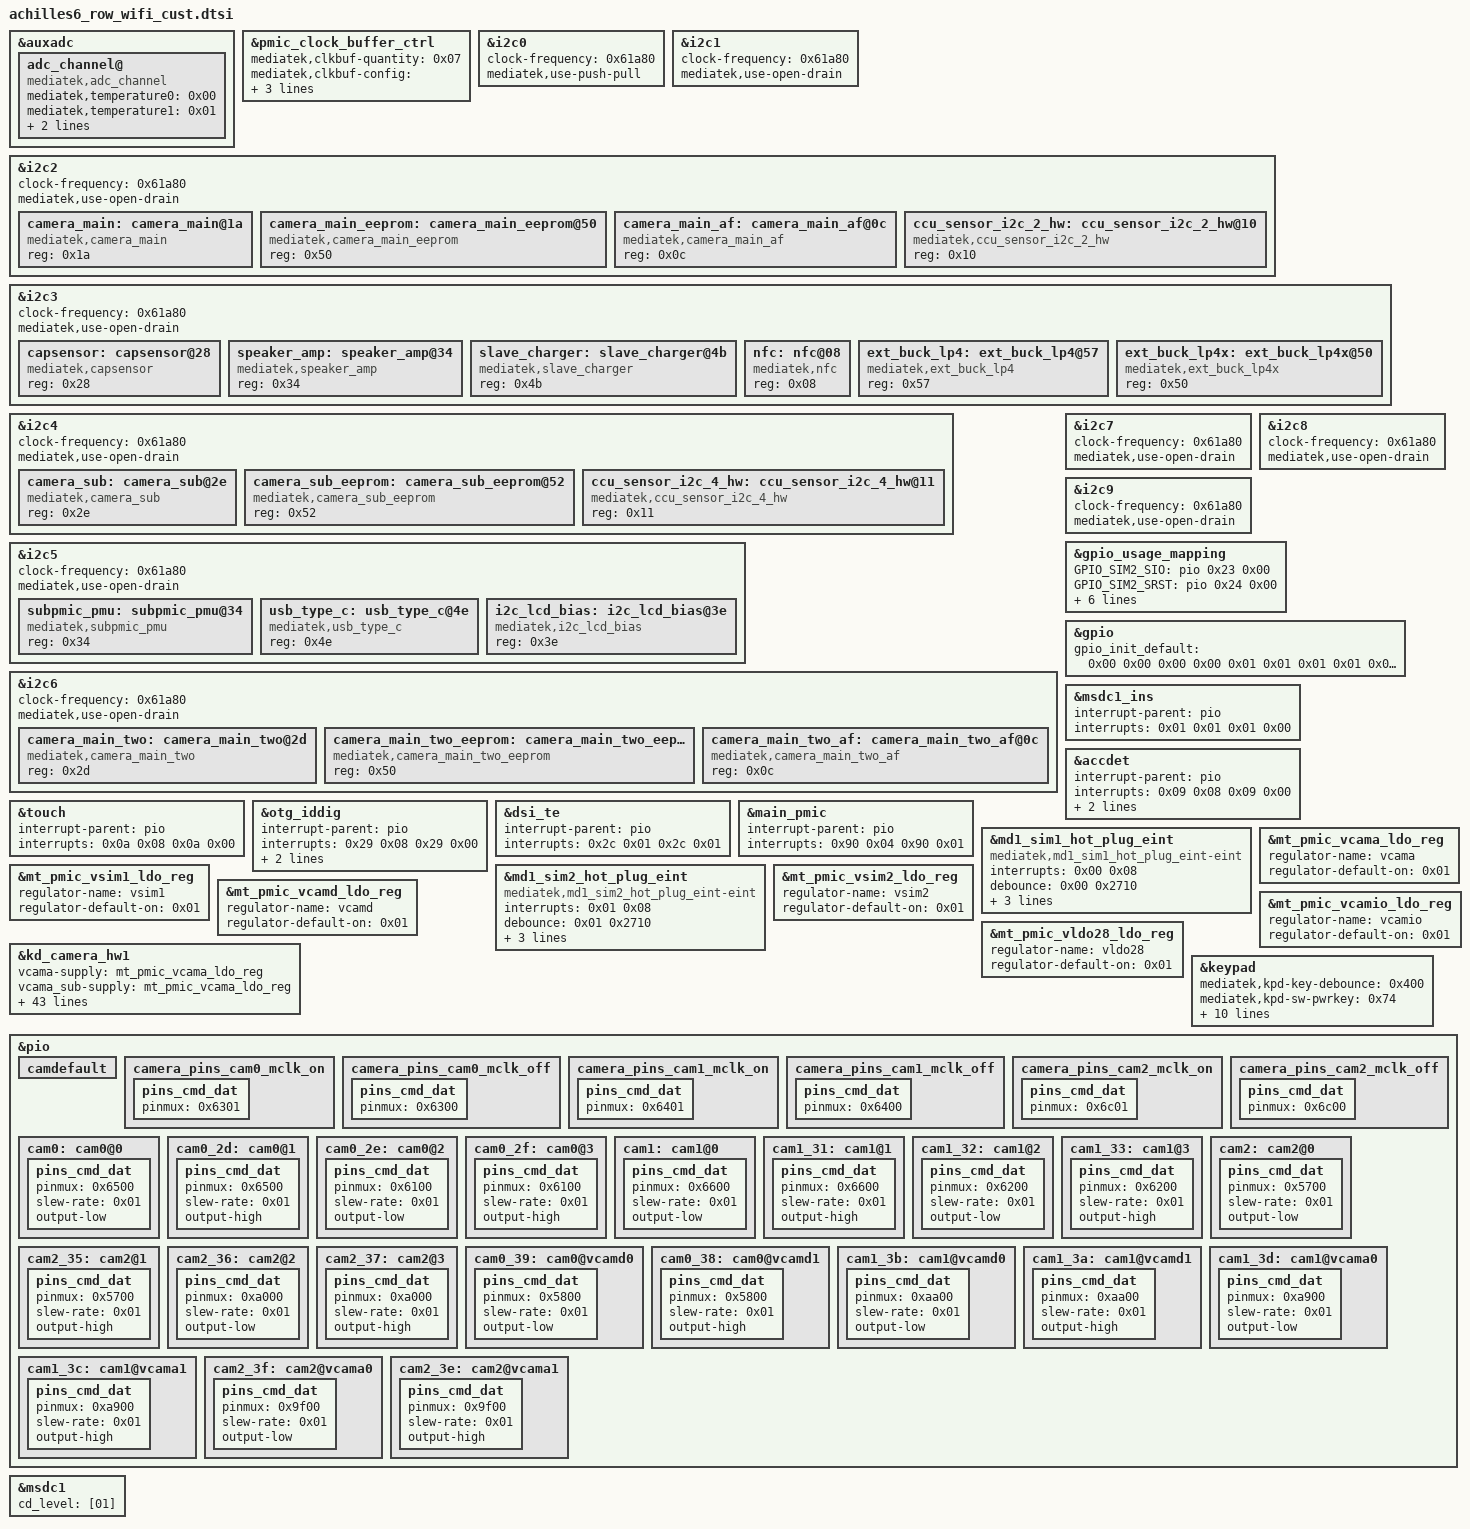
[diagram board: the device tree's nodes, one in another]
// SPDX-License-Identifier: GPL-2.0
/*
 * TB-X606F DrvGen output (GPIO, EINT, I2C, PMIC, KPD, camera pins), taken
 * from the stock Android 10 S301068 overlay. The 4.9 source drop's .dws is
 * older than the shipped hardware description, so it is not used.
 */

&auxadc {

	adc_channel@ {
		compatible = "mediatek,adc_channel";
		mediatek,temperature0 = <0x00>;
		mediatek,temperature1 = <0x01>;
		mediatek,adc_fdd_rf_params_dynamic_custom_ch = <0x02>;
		status = "okay";
	};
};

&pmic_clock_buffer_ctrl {
	mediatek,clkbuf-quantity = <0x07>;
	mediatek,clkbuf-config = <0x02 0x01 0x01 0x02 0x00 0x00 0x00>;
	mediatek,clkbuf-driving-current = <0x01 0x01 0x01 0x01 0x01 0x01 0x01>;
	status = "okay";
};

&i2c0 {
	#address-cells = <0x01>;
	#size-cells = <0x00>;
	clock-frequency = <0x61a80>;
	mediatek,use-push-pull;
};

&i2c1 {
	#address-cells = <0x01>;
	#size-cells = <0x00>;
	clock-frequency = <0x61a80>;
	mediatek,use-open-drain;
};

&i2c2 {
	#address-cells = <0x01>;
	#size-cells = <0x00>;
	clock-frequency = <0x61a80>;
	mediatek,use-open-drain;

	camera_main: camera_main@1a {
		compatible = "mediatek,camera_main";
		reg = <0x1a>;
		status = "okay";
	};

	camera_main_eeprom: camera_main_eeprom@50 {
		compatible = "mediatek,camera_main_eeprom";
		reg = <0x50>;
		status = "okay";
	};

	camera_main_af: camera_main_af@0c {
		compatible = "mediatek,camera_main_af";
		reg = <0x0c>;
		status = "okay";
	};

	ccu_sensor_i2c_2_hw: ccu_sensor_i2c_2_hw@10 {
		compatible = "mediatek,ccu_sensor_i2c_2_hw";
		reg = <0x10>;
		status = "okay";
	};
};

&i2c3 {
	#address-cells = <0x01>;
	#size-cells = <0x00>;
	clock-frequency = <0x61a80>;
	mediatek,use-open-drain;

	capsensor: capsensor@28 {
		compatible = "mediatek,capsensor";
		reg = <0x28>;
		status = "okay";
	};

	speaker_amp: speaker_amp@34 {
		compatible = "mediatek,speaker_amp";
		reg = <0x34>;
		status = "okay";
	};

	slave_charger: slave_charger@4b {
		compatible = "mediatek,slave_charger";
		reg = <0x4b>;
		status = "okay";
	};

	nfc: nfc@08 {
		compatible = "mediatek,nfc";
		reg = <0x08>;
		status = "okay";
	};

	ext_buck_lp4: ext_buck_lp4@57 {
		compatible = "mediatek,ext_buck_lp4";
		reg = <0x57>;
		status = "okay";
	};

	ext_buck_lp4x: ext_buck_lp4x@50 {
		compatible = "mediatek,ext_buck_lp4x";
		reg = <0x50>;
		status = "okay";
	};
};

&i2c4 {
	#address-cells = <0x01>;
	#size-cells = <0x00>;
	clock-frequency = <0x61a80>;
	mediatek,use-open-drain;

	camera_sub: camera_sub@2e {
		compatible = "mediatek,camera_sub";
		reg = <0x2e>;
		status = "okay";
	};

	camera_sub_eeprom: camera_sub_eeprom@52 {
		compatible = "mediatek,camera_sub_eeprom";
		reg = <0x52>;
		status = "okay";
	};

	ccu_sensor_i2c_4_hw: ccu_sensor_i2c_4_hw@11 {
		compatible = "mediatek,ccu_sensor_i2c_4_hw";
		reg = <0x11>;
		status = "okay";
	};
};

&i2c5 {
	#address-cells = <0x01>;
	#size-cells = <0x00>;
	clock-frequency = <0x61a80>;
	mediatek,use-open-drain;

	subpmic_pmu: subpmic_pmu@34 {
		compatible = "mediatek,subpmic_pmu";
		reg = <0x34>;
		status = "okay";
	};

	usb_type_c: usb_type_c@4e {
		compatible = "mediatek,usb_type_c";
		reg = <0x4e>;
		status = "okay";
	};

	i2c_lcd_bias: i2c_lcd_bias@3e {
		compatible = "mediatek,i2c_lcd_bias";
		reg = <0x3e>;
		status = "okay";
	};
};

&i2c6 {
	#address-cells = <0x01>;
	#size-cells = <0x00>;
	clock-frequency = <0x61a80>;
	mediatek,use-open-drain;

	camera_main_two: camera_main_two@2d {
		compatible = "mediatek,camera_main_two";
		reg = <0x2d>;
		status = "okay";
	};

	camera_main_two_eeprom: camera_main_two_eeprom@50 {
		compatible = "mediatek,camera_main_two_eeprom";
		reg = <0x50>;
		status = "okay";
	};

	camera_main_two_af: camera_main_two_af@0c {
		compatible = "mediatek,camera_main_two_af";
		reg = <0x0c>;
		status = "okay";
	};
};

&i2c7 {
	#address-cells = <0x01>;
	#size-cells = <0x00>;
	clock-frequency = <0x61a80>;
	mediatek,use-open-drain;
};

&i2c8 {
	#address-cells = <0x01>;
	#size-cells = <0x00>;
	clock-frequency = <0x61a80>;
	mediatek,use-open-drain;
};

&i2c9 {
	#address-cells = <0x01>;
	#size-cells = <0x00>;
	clock-frequency = <0x61a80>;
	mediatek,use-open-drain;
};

&gpio_usage_mapping {
	GPIO_SIM2_SIO = <&pio 0x23 0x00>;
	GPIO_SIM2_SRST = <&pio 0x24 0x00>;
	GPIO_SIM2_SCLK = <&pio 0x25 0x00>;
	GPIO_SIM1_SCLK = <&pio 0x26 0x00>;
	GPIO_SIM1_SRST = <&pio 0x27 0x00>;
	GPIO_SIM1_SIO = <&pio 0x28 0x00>;
	GPIO_SIM2_HOT_PLUG = <&pio 0x2e 0x00>;
	GPIO_SIM1_HOT_PLUG = <&pio 0x2f 0x00>;
};

&gpio {
	gpio_init_default = <
		0x00 0x00 0x00 0x00 0x01 0x01 0x01
		0x01 0x00 0x00 0x00 0x01 0x00 0x01
		0x02 0x00 0x00 0x00 0x00 0x00 0x01
		0x03 0x00 0x00 0x00 0x01 0x01 0x00
		0x04 0x00 0x00 0x00 0x01 0x01 0x00
		0x05 0x05 0x01 0x00 0x00 0x00 0x00
		0x06 0x00 0x01 0x00 0x01 0x01 0x00
		0x07 0x00 0x00 0x00 0x01 0x01 0x00
		0x08 0x07 0x00 0x00 0x01 0x01 0x00
		0x09 0x00 0x00 0x00 0x01 0x01 0x00
		0x0a 0x00 0x00 0x00 0x01 0x01 0x00
		0x0b 0x00 0x00 0x00 0x01 0x01 0x00
		0x0c 0x00 0x00 0x00 0x01 0x01 0x00
		0x0d 0x03 0x00 0x00 0x01 0x00 0x00
		0x0e 0x03 0x01 0x00 0x00 0x00 0x00
		0x0f 0x03 0x01 0x00 0x00 0x00 0x00
		0x10 0x03 0x01 0x00 0x00 0x00 0x00
		0x11 0x06 0x00 0x00 0x01 0x00 0x00
		0x12 0x06 0x01 0x00 0x00 0x00 0x00
		0x13 0x06 0x01 0x00 0x00 0x00 0x00
		0x14 0x06 0x01 0x00 0x00 0x00 0x00
		0x15 0x01 0x00 0x00 0x01 0x01 0x00
		0x16 0x01 0x01 0x00 0x01 0x00 0x00
		0x17 0x01 0x01 0x00 0x01 0x01 0x00
		0x18 0x01 0x01 0x00 0x01 0x00 0x00
		0x19 0x03 0x00 0x00 0x01 0x01 0x00
		0x1a 0x03 0x00 0x00 0x01 0x01 0x00
		0x1b 0x03 0x01 0x00 0x00 0x00 0x00
		0x1c 0x00 0x01 0x00 0x00 0x00 0x00
		0x1d 0x01 0x01 0x00 0x00 0x00 0x01
		0x1e 0x01 0x00 0x00 0x01 0x01 0x01
		0x1f 0x01 0x00 0x00 0x01 0x01 0x01
		0x20 0x01 0x00 0x00 0x01 0x01 0x01
		0x21 0x01 0x00 0x00 0x01 0x01 0x01
		0x22 0x01 0x00 0x00 0x01 0x01 0x01
		0x23 0x01 0x00 0x00 0x01 0x01 0x00
		0x24 0x01 0x01 0x00 0x00 0x00 0x00
		0x25 0x01 0x01 0x00 0x00 0x00 0x00
		0x26 0x01 0x01 0x00 0x00 0x00 0x00
		0x27 0x01 0x01 0x00 0x00 0x00 0x00
		0x28 0x01 0x00 0x00 0x01 0x01 0x00
		0x29 0x00 0x00 0x00 0x01 0x01 0x00
		0x2a 0x00 0x01 0x00 0x01 0x00 0x00
		0x2b 0x00 0x00 0x00 0x01 0x00 0x00
		0x2c 0x01 0x00 0x00 0x01 0x00 0x00
		0x2d 0x00 0x01 0x00 0x00 0x00 0x00
		0x2e 0x01 0x00 0x00 0x01 0x01 0x00
		0x2f 0x01 0x00 0x00 0x01 0x01 0x00
		0x30 0x01 0x00 0x00 0x01 0x01 0x01
		0x31 0x01 0x00 0x00 0x01 0x01 0x01
		0x32 0x01 0x00 0x00 0x01 0x01 0x01
		0x33 0x01 0x00 0x00 0x01 0x01 0x01
		0x34 0x01 0x01 0x00 0x01 0x00 0x00
		0x35 0x01 0x01 0x00 0x01 0x00 0x00
		0x36 0x01 0x01 0x00 0x01 0x00 0x00
		0x37 0x01 0x01 0x00 0x01 0x00 0x00
		0x38 0x01 0x01 0x00 0x01 0x00 0x00
		0x39 0x01 0x01 0x00 0x01 0x00 0x00
		0x3a 0x00 0x00 0x00 0x01 0x00 0x00
		0x3b 0x01 0x00 0x00 0x01 0x00 0x00
		0x3c 0x01 0x00 0x00 0x01 0x00 0x00
		0x3d 0x01 0x00 0x00 0x01 0x00 0x00
		0x3e 0x01 0x00 0x00 0x01 0x00 0x00
		0x3f 0x01 0x00 0x00 0x01 0x00 0x00
		0x40 0x01 0x00 0x00 0x01 0x00 0x00
		0x41 0x01 0x00 0x00 0x01 0x00 0x00
		0x42 0x01 0x00 0x00 0x01 0x00 0x00
		0x43 0x01 0x00 0x00 0x01 0x00 0x00
		0x44 0x01 0x00 0x00 0x01 0x00 0x00
		0x45 0x01 0x01 0x00 0x01 0x00 0x00
		0x46 0x01 0x01 0x00 0x01 0x00 0x00
		0x47 0x01 0x01 0x00 0x01 0x00 0x00
		0x48 0x01 0x01 0x00 0x01 0x00 0x00
		0x49 0x01 0x01 0x00 0x01 0x00 0x00
		0x4a 0x01 0x01 0x00 0x01 0x00 0x00
		0x4b 0x01 0x01 0x00 0x01 0x00 0x00
		0x4c 0x01 0x01 0x00 0x01 0x00 0x00
		0x4d 0x01 0x01 0x00 0x01 0x00 0x00
		0x4e 0x01 0x01 0x00 0x01 0x00 0x00
		0x4f 0x01 0x00 0x00 0x01 0x00 0x00
		0x50 0x01 0x00 0x00 0x01 0x00 0x00
		0x51 0x01 0x00 0x00 0x01 0x01 0x01
		0x52 0x01 0x00 0x00 0x01 0x01 0x01
		0x53 0x01 0x00 0x00 0x01 0x01 0x01
		0x54 0x01 0x00 0x00 0x01 0x01 0x01
		0x55 0x01 0x01 0x00 0x01 0x00 0x00
		0x56 0x01 0x01 0x00 0x01 0x00 0x00
		0x57 0x00 0x01 0x01 0x00 0x00 0x00
		0x58 0x00 0x01 0x00 0x01 0x00 0x00
		0x59 0x01 0x00 0x00 0x01 0x00 0x00
		0x5a 0x02 0x01 0x00 0x00 0x00 0x00
		0x5b 0x00 0x01 0x00 0x01 0x00 0x00
		0x5c 0x01 0x01 0x00 0x00 0x00 0x00
		0x5d 0x01 0x00 0x00 0x01 0x01 0x00
		0x5e 0x01 0x00 0x00 0x01 0x01 0x00
		0x5f 0x01 0x00 0x00 0x01 0x01 0x00
		0x60 0x01 0x01 0x00 0x00 0x00 0x00
		0x61 0x00 0x01 0x00 0x00 0x00 0x00
		0x62 0x00 0x01 0x00 0x00 0x00 0x00
		0x63 0x01 0x01 0x00 0x00 0x00 0x00
		0x64 0x01 0x01 0x00 0x00 0x00 0x00
		0x65 0x00 0x01 0x01 0x00 0x00 0x00
		0x66 0x00 0x01 0x01 0x00 0x00 0x00
		0x67 0x01 0x00 0x00 0x01 0x01 0x01
		0x68 0x01 0x00 0x00 0x01 0x01 0x01
		0x69 0x01 0x00 0x00 0x01 0x01 0x01
		0x6a 0x01 0x00 0x00 0x01 0x01 0x01
		0x6b 0x02 0x01 0x00 0x00 0x00 0x00
		0x6c 0x01 0x01 0x00 0x00 0x00 0x00
		0x6d 0x02 0x00 0x00 0x01 0x01 0x00
		0x6e 0x00 0x00 0x00 0x01 0x00 0x00
		0x6f 0x00 0x00 0x00 0x01 0x00 0x00
		0x70 0x00 0x00 0x00 0x01 0x00 0x00
		0x71 0x00 0x00 0x00 0x01 0x00 0x00
		0x72 0x00 0x00 0x00 0x01 0x00 0x00
		0x73 0x00 0x00 0x00 0x01 0x00 0x00
		0x74 0x00 0x00 0x00 0x01 0x00 0x00
		0x75 0x00 0x00 0x00 0x01 0x00 0x00
		0x76 0x00 0x00 0x00 0x01 0x00 0x00
		0x77 0x00 0x00 0x00 0x01 0x00 0x00
		0x78 0x00 0x00 0x00 0x01 0x00 0x00
		0x79 0x00 0x00 0x00 0x01 0x00 0x00
		0x7a 0x01 0x00 0x00 0x01 0x01 0x01
		0x7b 0x01 0x00 0x00 0x01 0x01 0x01
		0x7c 0x01 0x01 0x00 0x00 0x00 0x01
		0x7d 0x01 0x00 0x00 0x01 0x01 0x01
		0x7e 0x01 0x00 0x00 0x01 0x01 0x01
		0x7f 0x01 0x00 0x00 0x01 0x01 0x01
		0x80 0x01 0x00 0x00 0x01 0x01 0x01
		0x81 0x01 0x00 0x00 0x01 0x01 0x01
		0x82 0x01 0x00 0x00 0x01 0x01 0x01
		0x83 0x01 0x00 0x00 0x01 0x00 0x01
		0x84 0x01 0x00 0x00 0x01 0x01 0x01
		0x85 0x01 0x01 0x01 0x00 0x00 0x01
		0x86 0x01 0x00 0x00 0x01 0x00 0x01
		0x87 0x01 0x01 0x00 0x00 0x00 0x00
		0x88 0x01 0x01 0x00 0x00 0x00 0x00
		0x89 0x01 0x01 0x00 0x00 0x00 0x00
		0x8a 0x01 0x01 0x00 0x00 0x00 0x00
		0x8b 0x01 0x01 0x00 0x00 0x00 0x00
		0x8c 0x01 0x00 0x00 0x01 0x00 0x00
		0x8d 0x01 0x00 0x00 0x01 0x00 0x00
		0x8e 0x01 0x00 0x00 0x01 0x00 0x00
		0x8f 0x01 0x00 0x00 0x01 0x00 0x00
		0x90 0x01 0x00 0x00 0x01 0x00 0x00
		0x91 0x01 0x01 0x01 0x00 0x00 0x00
		0x92 0x01 0x00 0x00 0x01 0x00 0x00
		0x93 0x01 0x01 0x00 0x00 0x00 0x00
		0x94 0x01 0x01 0x00 0x00 0x00 0x00
		0x95 0x01 0x01 0x00 0x00 0x00 0x00
		0x96 0x06 0x00 0x00 0x01 0x01 0x00
		0x97 0x00 0x01 0x00 0x00 0x00 0x00
		0x98 0x00 0x00 0x00 0x00 0x00 0x00
		0x99 0x00 0x01 0x00 0x00 0x00 0x00
		0x9a 0x00 0x01 0x00 0x00 0x00 0x00
		0x9b 0x07 0x01 0x00 0x00 0x00 0x00
		0x9c 0x07 0x00 0x00 0x01 0x00 0x00
		0x9d 0x07 0x00 0x00 0x01 0x00 0x00
		0x9e 0x07 0x00 0x00 0x01 0x00 0x00
		0x9f 0x00 0x01 0x01 0x00 0x00 0x00
		0xa0 0x00 0x01 0x00 0x00 0x00 0x00
		0xa1 0x01 0x00 0x00 0x01 0x01 0x01
		0xa2 0x01 0x00 0x00 0x01 0x01 0x01
		0xa3 0x00 0x00 0x00 0x00 0x00 0x00
		0xa4 0x00 0x00 0x00 0x00 0x00 0x00
		0xa5 0x00 0x00 0x00 0x01 0x00 0x00
		0xa6 0x00 0x00 0x00 0x01 0x00 0x00
		0xa7 0x00 0x01 0x00 0x01 0x01 0x00
		0xa8 0x00 0x01 0x00 0x01 0x01 0x00
		0xa9 0x00 0x01 0x00 0x00 0x00 0x00
		0xaa 0x00 0x00 0x00 0x00 0x00 0x00
		0xab 0x00 0x00 0x00 0x01 0x00 0x00
		0xac 0x00 0x01 0x00 0x00 0x00 0x00
		0xad 0x00 0x01 0x00 0x00 0x00 0x00
		0xae 0x00 0x01 0x00 0x00 0x00 0x00
		0xaf 0x00 0x01 0x00 0x00 0x00 0x00
		0xb0 0x00 0x01 0x00 0x00 0x00 0x00
		0xb1 0x00 0x01 0x00 0x00 0x00 0x00
		0xb2 0x00 0x01 0x01 0x01 0x01 0x00
		0xb3 0x00 0x00 0x00 0x01 0x00 0x00
	>;
};

&msdc1_ins {
	interrupt-parent = <&pio>;
	interrupts = <0x01 0x01 0x01 0x00>;
	status = "okay";
};

&accdet {
	interrupt-parent = <&pio>;
	interrupts = <0x09 0x08 0x09 0x00>;
	deb-gpios = <&pio 0x09 0x00>;
	debounce = <0x3e800>;
	status = "okay";
};

&touch {
	interrupt-parent = <&pio>;
	interrupts = <0x0a 0x08 0x0a 0x00>;
	status = "okay";
};

&otg_iddig {
	interrupt-parent = <&pio>;
	interrupts = <0x29 0x02 0x29 0x00>;
	status = "okay";
};

&dsi_te {
	interrupt-parent = <&pio>;
	interrupts = <0x2c 0x01 0x2c 0x01>;
	status = "okay";
};

&main_pmic {
	interrupt-parent = <&pio>;
	interrupts = <0x90 0x04 0x90 0x01>;
	status = "okay";
};

&md1_sim1_hot_plug_eint {
	compatible = "mediatek,md1_sim1_hot_plug_eint-eint";
	interrupts = <0x00 0x08>;
	debounce = <0x00 0x2710>;
	dedicated = <0x00 0x00>;
	src_pin = <0x00 0x01>;
	sockettype = <0x00 0x00>;
	status = "okay";
};

&md1_sim2_hot_plug_eint {
	compatible = "mediatek,md1_sim2_hot_plug_eint-eint";
	interrupts = <0x01 0x08>;
	debounce = <0x01 0x2710>;
	dedicated = <0x01 0x00>;
	src_pin = <0x01 0x02>;
	sockettype = <0x01 0x00>;
	status = "okay";
};

&mt_pmic_vcama_ldo_reg {
	regulator-name = "vcama";
	regulator-default-on = <0x01>;
	status = "okay";
};

&mt_pmic_vsim1_ldo_reg {
	regulator-name = "vsim1";
	regulator-default-on = <0x01>;
	status = "okay";
};

&mt_pmic_vsim2_ldo_reg {
	regulator-name = "vsim2";
	regulator-default-on = <0x01>;
	status = "okay";
};

&mt_pmic_vcamd_ldo_reg {
	regulator-name = "vcamd";
	regulator-default-on = <0x01>;
	status = "okay";
};

&mt_pmic_vcamio_ldo_reg {
	regulator-name = "vcamio";
	regulator-default-on = <0x01>;
	status = "okay";
};

&mt_pmic_vldo28_ldo_reg {
	regulator-name = "vldo28";
	regulator-default-on = <0x01>;
	status = "okay";
};

&kd_camera_hw1 {
	vcama-supply = <&mt_pmic_vcama_ldo_reg>;
	vcama_sub-supply = <&mt_pmic_vcama_ldo_reg>;
	vcamd_main2-supply = <&mt_pmic_vcamd_ldo_reg>;
	vcamd_sub-supply = <&mt_pmic_vcamd_ldo_reg>;
	vcamio-supply = <&mt_pmic_vcamio_ldo_reg>;
	vcamio_sub-supply = <&mt_pmic_vcamio_ldo_reg>;
	vcamio_main2-supply = <&mt_pmic_vcamio_ldo_reg>;
	vcamaf-supply = <&mt_pmic_vldo28_ldo_reg>;
	status = "okay";
};

&touch {
	status = "okay";
};

&keypad {
	mediatek,kpd-key-debounce = <0x400>;
	mediatek,kpd-sw-pwrkey = <0x74>;
	mediatek,kpd-hw-pwrkey = <0x08>;
	mediatek,kpd-use-extend-type = <0x00>;
	mediatek,kpd-hw-map-num = <0x48>;
	mediatek,kpd-hw-init-map = <
		0x73 0x72 0x00 0x00 0x00 0x00 0x00 0x00
		0x00 0x00 0x00 0x00 0x00 0x00 0x00 0x00
		0x00 0x00 0x00 0x00 0x00 0x00 0x00 0x00
		0x00 0x00 0x00 0x00 0x00 0x00 0x00 0x00
		0x00 0x00 0x00 0x00 0x00 0x00 0x00 0x00
		0x00 0x00 0x00 0x00 0x00 0x00 0x00 0x00
		0x00 0x00 0x00 0x00 0x00 0x00 0x00 0x00
		0x00 0x00 0x00 0x00 0x00 0x00 0x00 0x00
		0x00 0x00 0x00 0x00 0x00 0x00 0x00 0x00
	>;
	mediatek,kpd-pwrkey-eint-gpio = <0x00>;
	mediatek,kpd-pwkey-gpio-din = <0x00>;
	mediatek,kpd-hw-dl-key2 = <0x08>;
	mediatek,kpd-hw-recovery-key = <0x00>;
	mediatek,kpd-hw-factory-key = <0x01>;
	status = "okay";
};

&pio {

	camdefault: camdefault {
	};

	camera_pins_cam0_mclk_on: camera_pins_cam0_mclk_on {

		pins_cmd_dat {
			pinmux = <0x6301>;
		};
	};

	camera_pins_cam0_mclk_off: camera_pins_cam0_mclk_off {

		pins_cmd_dat {
			pinmux = <0x6300>;
		};
	};

	camera_pins_cam1_mclk_on: camera_pins_cam1_mclk_on {

		pins_cmd_dat {
			pinmux = <0x6401>;
		};
	};

	camera_pins_cam1_mclk_off: camera_pins_cam1_mclk_off {

		pins_cmd_dat {
			pinmux = <0x6400>;
		};
	};

	camera_pins_cam2_mclk_on: camera_pins_cam2_mclk_on {

		pins_cmd_dat {
			pinmux = <0x6c01>;
		};
	};

	camera_pins_cam2_mclk_off: camera_pins_cam2_mclk_off {

		pins_cmd_dat {
			pinmux = <0x6c00>;
		};
	};

	cam0: cam0@0 {

		pins_cmd_dat {
			pinmux = <0x6500>;
			slew-rate = <0x01>;
			output-low;
		};
	};

	cam0_2d: cam0@1 {

		pins_cmd_dat {
			pinmux = <0x6500>;
			slew-rate = <0x01>;
			output-high;
		};
	};

	cam0_2e: cam0@2 {

		pins_cmd_dat {
			pinmux = <0x6100>;
			slew-rate = <0x01>;
			output-low;
		};
	};

	cam0_2f: cam0@3 {

		pins_cmd_dat {
			pinmux = <0x6100>;
			slew-rate = <0x01>;
			output-high;
		};
	};

	cam1: cam1@0 {

		pins_cmd_dat {
			pinmux = <0x6600>;
			slew-rate = <0x01>;
			output-low;
		};
	};

	cam1_31: cam1@1 {

		pins_cmd_dat {
			pinmux = <0x6600>;
			slew-rate = <0x01>;
			output-high;
		};
	};

	cam1_32: cam1@2 {

		pins_cmd_dat {
			pinmux = <0x6200>;
			slew-rate = <0x01>;
			output-low;
		};
	};

	cam1_33: cam1@3 {

		pins_cmd_dat {
			pinmux = <0x6200>;
			slew-rate = <0x01>;
			output-high;
		};
	};

	cam2: cam2@0 {

		pins_cmd_dat {
			pinmux = <0x5700>;
			slew-rate = <0x01>;
			output-low;
		};
	};

	cam2_35: cam2@1 {

		pins_cmd_dat {
			pinmux = <0x5700>;
			slew-rate = <0x01>;
			output-high;
		};
	};

	cam2_36: cam2@2 {

		pins_cmd_dat {
			pinmux = <0xa000>;
			slew-rate = <0x01>;
			output-low;
		};
	};

	cam2_37: cam2@3 {

		pins_cmd_dat {
			pinmux = <0xa000>;
			slew-rate = <0x01>;
			output-high;
		};
	};

	cam0_39: cam0@vcamd0 {

		pins_cmd_dat {
			pinmux = <0x5800>;
			slew-rate = <0x01>;
			output-low;
		};
	};

	cam0_38: cam0@vcamd1 {

		pins_cmd_dat {
			pinmux = <0x5800>;
			slew-rate = <0x01>;
			output-high;
		};
	};

	cam1_3b: cam1@vcamd0 {

		pins_cmd_dat {
			pinmux = <0xaa00>;
			slew-rate = <0x01>;
			output-low;
		};
	};

	cam1_3a: cam1@vcamd1 {

		pins_cmd_dat {
			pinmux = <0xaa00>;
			slew-rate = <0x01>;
			output-high;
		};
	};

	cam1_3d: cam1@vcama0 {

		pins_cmd_dat {
			pinmux = <0xa900>;
			slew-rate = <0x01>;
			output-low;
		};
	};

	cam1_3c: cam1@vcama1 {

		pins_cmd_dat {
			pinmux = <0xa900>;
			slew-rate = <0x01>;
			output-high;
		};
	};

	cam2_3f: cam2@vcama0 {

		pins_cmd_dat {
			pinmux = <0x9f00>;
			slew-rate = <0x01>;
			output-low;
		};
	};

	cam2_3e: cam2@vcama1 {

		pins_cmd_dat {
			pinmux = <0x9f00>;
			slew-rate = <0x01>;
			output-high;
		};
	};
};

&kd_camera_hw1 {
	pinctrl-names = "default\0cam0_rst0\0cam0_rst1\0cam0_pnd0\0cam0_pnd1\0cam1_rst0\0cam1_rst1\0cam1_pnd0\0cam1_pnd1\0cam2_rst0\0cam2_rst1\0cam2_pnd0\0cam2_pnd1\0cam0_vcamd_on\0cam0_vcamd_off\0cam1_vcamd_on\0cam1_vcamd_off\0cam1_vcama_on\0cam1_vcama_off\0cam2_vcama_on\0cam2_vcama_off\0cam0_mclk_on\0cam0_mclk_off\0cam1_mclk_on\0cam1_mclk_off\0cam2_mclk_on\0cam2_mclk_off";
	pinctrl-0 = <&camdefault>;
	pinctrl-1 = <&cam0>;
	pinctrl-2 = <&cam0_2d>;
	pinctrl-3 = <&cam0_2e>;
	pinctrl-4 = <&cam0_2f>;
	pinctrl-5 = <&cam1>;
	pinctrl-6 = <&cam1_31>;
	pinctrl-7 = <&cam1_32>;
	pinctrl-8 = <&cam1_33>;
	pinctrl-9 = <&cam2>;
	pinctrl-10 = <&cam2_35>;
	pinctrl-11 = <&cam2_36>;
	pinctrl-12 = <&cam2_37>;
	pinctrl-13 = <&cam0_38>;
	pinctrl-14 = <&cam0_39>;
	pinctrl-15 = <&cam1_3a>;
	pinctrl-16 = <&cam1_3b>;
	pinctrl-17 = <&cam1_3c>;
	pinctrl-18 = <&cam1_3d>;
	pinctrl-19 = <&cam2_3e>;
	pinctrl-20 = <&cam2_3f>;
	pinctrl-21 = <&camera_pins_cam0_mclk_on>;
	pinctrl-22 = <&camera_pins_cam0_mclk_off>;
	pinctrl-23 = <&camera_pins_cam1_mclk_on>;
	pinctrl-24 = <&camera_pins_cam1_mclk_off>;
	pinctrl-25 = <&camera_pins_cam2_mclk_on>;
	pinctrl-26 = <&camera_pins_cam2_mclk_off>;
	cam0_vcama-supply = <&mt_pmic_vcama_ldo_reg>;
	cam0_vcamd-supply = <&mt_pmic_vcamd_ldo_reg>;
	cam0_vcamio-supply = <&mt_pmic_vcamio_ldo_reg>;
	cam1_vcama-supply = <&mt_pmic_vcama_ldo_reg>;
	cam1_vcamd-supply = <&mt_pmic_vcamd_ldo_reg>;
	cam1_vcamio-supply = <&mt_pmic_vcamio_ldo_reg>;
	cam0_enable_sensor = "s5k4h7yxqtech1_mipi_raw s5k4h7yx_mipi_raw ov13b10_mipi_raw s5k4h7yxqtech_mipi_raw ov13b10qtech_mipi_raw";
	cam1_enable_sensor = "gc5035_mipi_raw s5k4h7yxfront_mipi_raw gc5035kingcome_mipi_raw s5k4h7yxlcetron_mipi_raw ov5675_mipi_raw";
	status = "okay";
};

&otg_iddig {
	status = "okay";
	interrupt-parent = <&pio>;
	interrupts = <0x29 0x08 0x29 0x00>;
	usb,vbus_gpio = <&pio 0xa9 0x00>;
	usb,vbus_gpio_num = <0xa9>;
};

&msdc1 {
	cd_level = [01];
};
